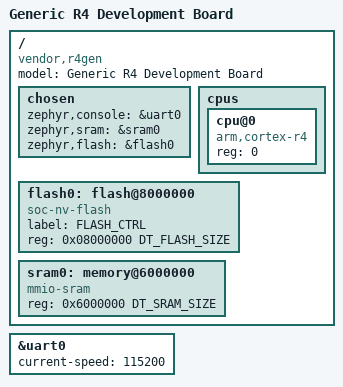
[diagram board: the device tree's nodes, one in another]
/*
 * Copyright (c) 2017, embedjournal.com
 *
 * SPDX-License-Identifier: Apache-2.0
 */

/dts-v1/;
#include <arm/vendor/r4soc.dtsi>

#define __SIZE_K(x) (x * 1024)
#define __SIZE_M(x) (__SIZE_K(x) * 1024)
#define DT_FLASH_SIZE       __SIZE_K(64)
#define DT_SRAM_SIZE        __SIZE_M(8)

/ {
	model = "Generic R4 Development Board";
	compatible = "vendor,r4gen";

	chosen {
		zephyr,console = &uart0;
		zephyr,sram = &sram0;
		zephyr,flash = &flash0;
	};

	cpus {
		#address-cells = <1>;
		#size-cells = <0>;

		cpu@0 {
			device_type = "cpu";
			compatible = "arm,cortex-r4";
			reg = <0>;
		};
	};

	flash0: flash@8000000 {
		compatible = "soc-nv-flash";
		label = "FLASH_CTRL";
		reg = <0x08000000 DT_FLASH_SIZE>;
	};

	sram0: memory@6000000 {
		device_type = "memory";
		compatible = "mmio-sram";
		reg = <0x6000000 DT_SRAM_SIZE>;
	};
};

&uart0 {
	status = "ok";
	current-speed = <115200>;
};
